# cslr_intc_001 register map
Vendor: Texas Instruments
Peripheral module from a debugger description file.
Registers are 32-bit, access not given, reset 0x77777777 unless marked. A register's access mark holds for its fields unless they carry their own. Offsets are as the file gives them; lines under a group give offsets from that group; [hi:lo] are bit positions; {n}, {i} and the like mark numbered series; 'fields as' and 'values as' point back to an identical list; <NAME> marks a mode.

## INTC — Interrupt Controller
0x00 FIQ0 rw reset 0x1 — Interrupt Status of INT[31:0] (if mapped to FIQ)
  [31:0] FIQ_31_0 — Interrupt Status of INTx, if mapped to FIQ
    0=INT (Rd: Interrupt occurred); 1=ACK (Wr: Acknowledge interrupt)
0x04 FIQ1 rw reset 0x1 — Interrupt Status of INT[63:32] (if mapped to FIQ)
  [31:0] FIQ_63_32 — Interrupt Status of INTx, if mapped to FIQ
    values as FIQ0.FIQ_31_0
0x08 IRQ0 rw reset 0x1 — Interrupt Status of INT[31:0] (if mapped to IRQ)
  [31:0] IRQ_31_0 — Interrupt Status of INTx, if mapped to IRQ
    values as FIQ0.FIQ_31_0
0x0C IRQ1 rw reset 0x1 — Interrupt Status of INT[63:32] (if mapped to IRQ)
  [31:0] IRQ_63_32 — Interrupt Status of INTx, if mapped to IRQ
    values as FIQ0.FIQ_31_0
0x10 FIQENTRY reset 0x0 — Entry Address[28:0] for valid FIQ interrupt
  [28:0] FIQENTRY ro — Interrupt Entry Table Address (of the current highest priority FIQ)
0x14 IRQENTRY reset 0x0 — Entry Address[28:0] for valid IRQ interrupt
  [28:0] IRQENTRY ro — Interrupt Entry Table Address (of the current highest priority IRQ)
0x18 EINT0 rw reset 0x0 — Interrupt Enable Register 0
  [31:0] EINT_31_0 — Interrupt Enable for INTx
    0=DISABLE (Mask Interrupt); 1=ENABLE (Enable Interrupt)
0x1C EINT1 rw reset 0x0 — Interrupt Enable Register 1
  [31:0] EINT_63_32 — Interrupt Enable for INTx
    0=DISABLE (Mask Interrupt); 1=ENABLE (Enable Interrupt)
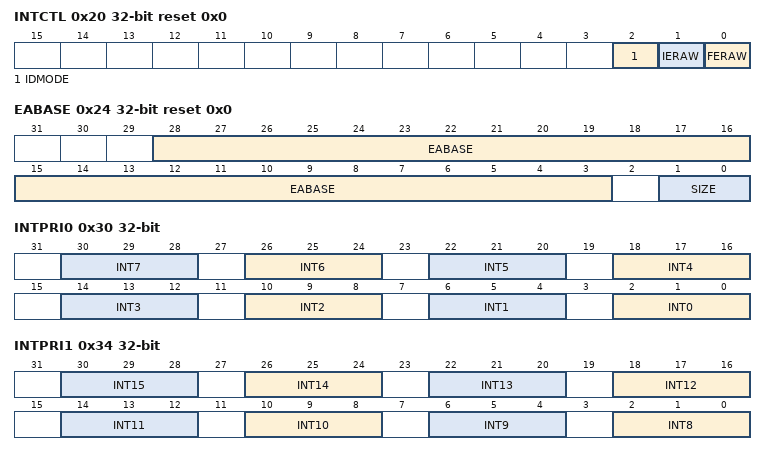
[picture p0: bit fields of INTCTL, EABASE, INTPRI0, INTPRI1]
0x20 INTCTL reset 0x0 — Interrupt Operation Control Register
  [2] IDMODE rw — Interrupt disable mode
    0=IMMEDIATE (Disabled immediately); 1=AFTERACK (Disabled after ack)
  [1] IERAW rw — Masked Interrupt Reflect in IRQENTRY Register
    0=DISABLE (Disable Reflect); 1=ENABLE (Enable Reflect)
  [0] FERAW rw — Masked Interrupt Reflect in FIQENTRY Register
    0=DISABLE (Disable Reflect); 1=ENABLE (Enable Reflect)
0x24 EABASE reset 0x0 — Interrupt Entry Table Base Address
  [28:3] EABASE rw — Interrupt Entry Table Base Address (8-byte aligned)
  [1:0] SIZE rw — Size of each entry in Interrupt Entry Table
    0=4BYTE (4 bytes); 1=8BYTE (8 bytes); 2=16BYTE (16 bytes); 3=32BYTE (32 bytes)
0x30 INTPRI0 — Interrupt 0-7 Priority select
  [4n+2:4n] INT{n} rw (n=0..7) — Selects INT{n} priority level
0x34 INTPRI1 — Interrupt 8-15 Priority select
  [4n-30:4n-32] INT{n} rw (n=8..15) — Selects INT{n} priority level
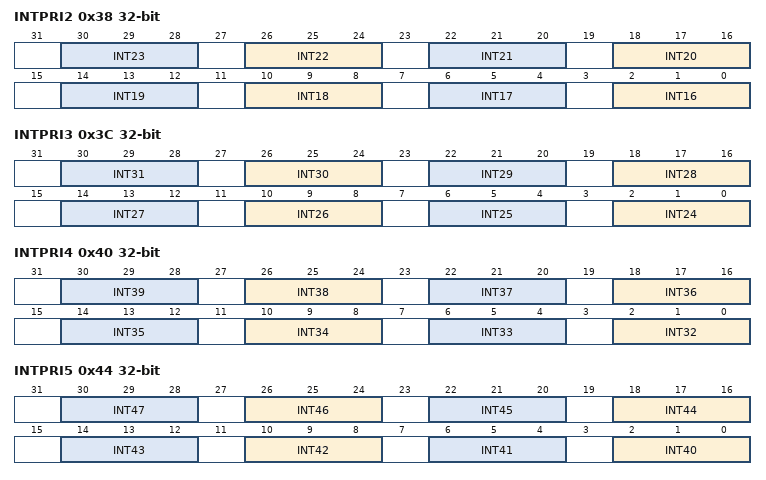
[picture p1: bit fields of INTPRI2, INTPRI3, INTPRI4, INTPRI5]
0x38 INTPRI2 — Interrupt 16-23 Priority select
  [4n-62:4n-64] INT{n} rw (n=16..23) — Selects INT{n} priority level
0x3C INTPRI3 — Interrupt 24-31 Priority select
  [4n-94:4n-96] INT{n} rw (n=24..31) — Selects INT{n} priority level
0x40 INTPRI4 — Interrupt 32-39 Priority select
  [4n-126:4n-128] INT{n} rw (n=32..39) — Selects INT{n} priority level
0x44 INTPRI5 — Interrupt 40-47 Priority select
  [4n-158:4n-160] INT{n} rw (n=40..47) — Selects INT{n} priority level
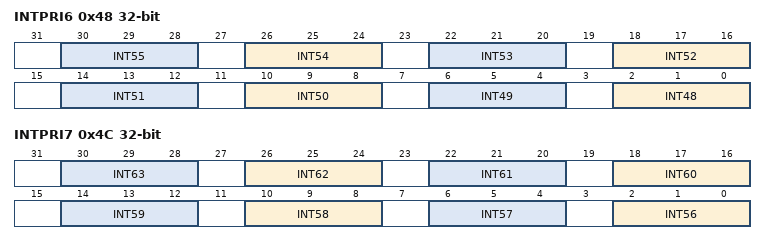
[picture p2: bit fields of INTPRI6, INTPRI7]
0x48 INTPRI6 — Interrupt 48-55 Priority select
  [4n-190:4n-192] INT{n} rw (n=48..55) — Selects INT{n} priority level
0x4C INTPRI7 — Interrupt 56-63 Priority select
  [4n-222:4n-224] INT{n} rw (n=56..63) — Selects INT{n} priority level
